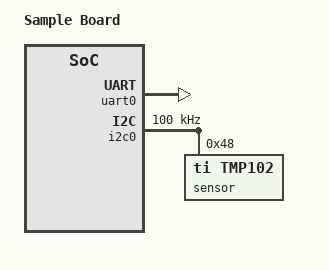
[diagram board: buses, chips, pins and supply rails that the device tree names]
/dts-v1/;

/ {
    model = "Sample Board";
    compatible = "vendor,sample-board";
    #address-cells = <1>;
    #size-cells = <1>;

    aliases {
        serial0 = &uart0;
        i2c0 = &i2c0;
    };

    uart0: serial@40001000 {
        compatible = "ns16550a";
        reg = <0x40001000 0x1000>;
        clock-frequency = <48000000>;
        interrupts = <5>;
        status = "okay";
    };

    i2c0: i2c@40002000 {
        compatible = "sample,i2c";
        reg = <0x40002000 0x100>;
        clock-frequency = <100000>;
        status = "okay";

        sensor@48 {
            compatible = "ti,tmp102";
            reg = <0x48>;
        };
    };

    gpio0: gpio@40003000 {
        compatible = "sample,gpio";
        reg = <0x40003000 0x100>;
        gpio-controller;
        #gpio-cells = <2>;
        ngpios = <32>;
    };
};
